# AE302F40C1537LE_CM55_HP_View register map
Vendor: Alif Semiconductor; Series: E3; File version: 1.0
CPU: CM55 r1p0, selectable endian, MPU, FPU, double-precision FPU, DSP, VTOR, 8 interrupt priority bits, 1 SAU regions
Registers are 32-bit, read-write, reset 0x0 unless marked. A register's access mark holds for its fields unless they carry their own. Offsets are from the block's base; [hi:lo] are bit positions; 'fields as' and 'values as' point back to an identical list.

## AON
Base 0x1A604000
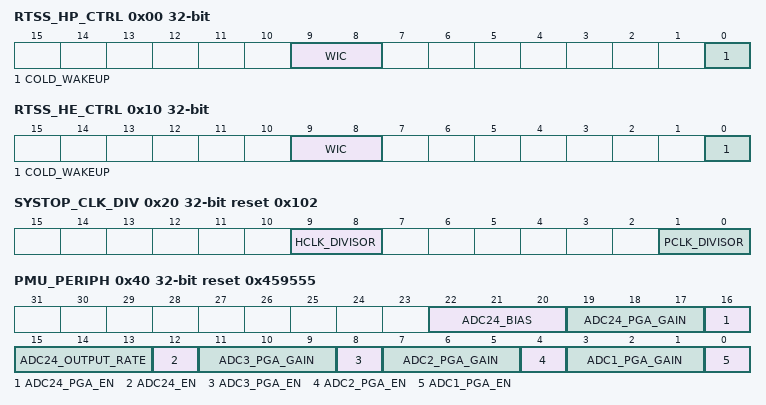
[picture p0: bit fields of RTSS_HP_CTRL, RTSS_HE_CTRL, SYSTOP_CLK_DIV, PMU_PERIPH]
0x00 RTSS_HP_CTRL — M55-HP Control Register
  [9:8] WIC — Control bits mapped to WICCONTROL[1:0] configuration signal of M55-HP. Bit [9] is mapped to WICCONTROL[1]. Bit [8] is mapped to WICCONTROL[0]. For more information, refer to Arm(R) Cortex(R)-M55 Processor Technical Reference Manual.
  [0] COLD_WAKEUP — Set this bit to wake up M55-HP power domain during cold boot or waking-up from stop mode, clear it once power-on sequence is complete to enable dynamic power transitions of M55-HP.
0x04 RTSS_HP_RESET reset 0x1 — M55-HP Reset Status Register
  [5:0] RESETSYNDROME wo write-1-clears — Reset status set by hardware and cleared by software
    0=The last reset of M55-HP was caused by POR or Secure Enclave initiated reset; 1=The last reset of M55-HP was caused by NSRST pin being asserted; 4=The last reset of M55-HP was caused by a reset request to the power domain
0x10 RTSS_HE_CTRL — M55-HE Control Register
  [9:8] WIC — Control bits mapped to WICCONTROL[1:0] configuration signal of M55-HE. Bit [9] is mapped to WICCONTROL[1]. Bit [8] is mapped to WICCONTROL[0]. For more information, refer to Arm(R) Cortex(R)-M55 Processor Technical Reference Manual.
  [0] COLD_WAKEUP — Set this bit to wake up M55-HE power domain during cold boot or waking-up from stop mode, clear it once power-on sequence is complete to enable dynamic power transitions of M55-HE.
0x14 RTSS_HE_RESET reset 0x1 — M55-HE Reset Status Register
  [5:0] RESETSYNDROME wo write-1-clears — Reset status set by hardware and cleared by software
    0=The last reset of M55-HE was caused by POR or Secure Enclave initiated reset; 1=The last reset of M55-HE was caused by NSRST pin being asserted; 4=The last reset of M55-HE was caused by a reset request to the power domain
0x1C RTSS_HE_LPUART_CKEN — LPUART Clock Enable Register
  [0] UART_CKEN — Enable clock for LPUART
    0=Disable clock; 1=Enable clock
0x20 SYSTOP_CLK_DIV reset 0x102 — System Bus Clock Divider Control Register
  [9:8] HCLK_DIVISOR — SYST_HCLK clock divisor
    0=Divide by 1; 1=Divide by 2; 2=Divide by 4; 3=Divide by 4
  [1:0] PCLK_DIVISOR — SYST_PCLK clock divisor
    0=Divide by 1; 1=Divide by 2; 2=Divide by 4; 3=Divide by 4
0x30 MISC_REG1 — HFXO Divider Control Register
  [16:13] CLKDIV — HFXO divisor
    0=Divide by 1; 1=Divide by 2; 2=Divide by 4; 3=Divide by 8; 4=Divide by 16; 5=Divide by 32; 6=Divide by 64; 7=Divide by 128; 8=Divide by 1; 9=Divide by 2; 10=Divide by 4; 11=Divide by 16; 12=Divide by 64; 13=Divide by 128; 14=Divide by 256; 15=Divide by 1024
0x40 PMU_PERIPH reset 0x459555 — ADC Control Register
  [22:20] ADC24_BIAS — ADC24 bias control
  [19:17] ADC24_PGA_GAIN — ADC24 PGA gain value
    0=0 dB; 1=6 dB; 2=12 dB; 3=18 dB; 4=24 dB; 5=30 dB; 6=36 dB; 7=42 dB
  [16] ADC24_PGA_EN — ADC24 PGA enable
    0=Disabled; 1=Enabled
  [15:13] ADC24_OUTPUT_RATE — ADC24 output rate select
  [12] ADC24_EN — ADC24 enable
    0=Disabled; 1=Enabled
  [11:9] ADC3_PGA_GAIN — ADC122 PGA gain value select
    values as ADC24_PGA_GAIN
  [8] ADC3_PGA_EN — ADC122 PGA enable Note: ADC122 must be put into differential mode when PGA is enabled
    0=Disabled; 1=Enabled
  [7:5] ADC2_PGA_GAIN — ADC121 PGA gain value select
    values as ADC24_PGA_GAIN
  [4] ADC2_PGA_EN — ADC121 PGA enable Note: ADC121 must be put into differential mode when PGA is enabled
    0=Disabled; 1=Enabled
  [3:1] ADC1_PGA_GAIN — ADC120 PGA gain value select
    values as ADC24_PGA_GAIN
  [0] ADC1_PGA_EN — ADC120 PGA enable Note: ADC120 must be put into differential mode when PGA is enabled
    0=Disabled; 1=Enabled
